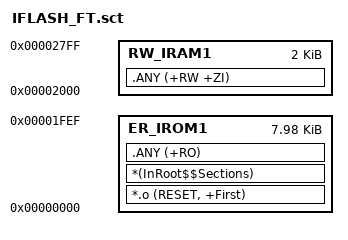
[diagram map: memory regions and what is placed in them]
; *************************************************************
; *** Scatter-Loading Description File generated by uVision ***
; *************************************************************

LR_IROM1 0x00000000 0x00001FF0  {    ; load region size_region
  ER_IROM1 0x00000000 0x00001FF0  {  ; load address = execution address
   *.o (RESET, +First)
   *(InRoot$$Sections)
   .ANY (+RO)
  }
  RW_IRAM1 0x00002000 0x00000800  {  ; RW data
   .ANY (+RW +ZI)
  }
}

